VERSION ""

NS_ :

BS_:

BU_: ECU Display VCU SteeringWheel WirelessGateway DATA_COLLECTION_INTEGRAL PDM FanController BMS_Master Competition_Meter FS_Datalogger Chroma LegacyCharger Tools BrakePedalAngleSensor

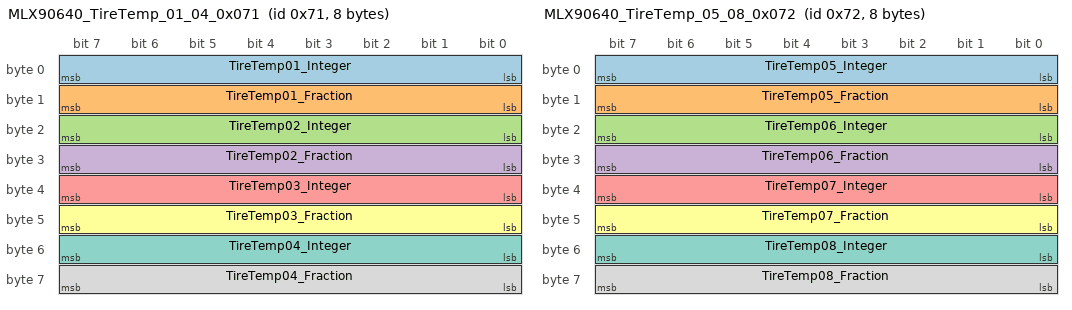
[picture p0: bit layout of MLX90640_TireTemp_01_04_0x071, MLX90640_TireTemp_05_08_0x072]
BO_ 113 MLX90640_TireTemp_01_04_0x071: 8 DATA_COLLECTION_INTEGRAL
 SG_ TireTemp01_Integer : 0|8@1+ (1,0) [0|255] "degC"  Display,WirelessGateway
 SG_ TireTemp01_Fraction : 8|8@1+ (0.01,0) [0|0.99] "degC"  Display,WirelessGateway
 SG_ TireTemp02_Integer : 16|8@1+ (1,0) [0|255] "degC"  Display,WirelessGateway
 SG_ TireTemp02_Fraction : 24|8@1+ (0.01,0) [0|0.99] "degC"  Display,WirelessGateway
 SG_ TireTemp03_Integer : 32|8@1+ (1,0) [0|255] "degC"  Display,WirelessGateway
 SG_ TireTemp03_Fraction : 40|8@1+ (0.01,0) [0|0.99] "degC"  Display,WirelessGateway
 SG_ TireTemp04_Integer : 48|8@1+ (1,0) [0|255] "degC"  Display,WirelessGateway
 SG_ TireTemp04_Fraction : 56|8@1+ (0.01,0) [0|0.99] "degC"  Display,WirelessGateway

BO_ 114 MLX90640_TireTemp_05_08_0x072: 8 DATA_COLLECTION_INTEGRAL
 SG_ TireTemp05_Integer : 0|8@1+ (1,0) [0|255] "degC"  Display,WirelessGateway
 SG_ TireTemp05_Fraction : 8|8@1+ (0.01,0) [0|0.99] "degC"  Display,WirelessGateway
 SG_ TireTemp06_Integer : 16|8@1+ (1,0) [0|255] "degC"  Display,WirelessGateway
 SG_ TireTemp06_Fraction : 24|8@1+ (0.01,0) [0|0.99] "degC"  Display,WirelessGateway
 SG_ TireTemp07_Integer : 32|8@1+ (1,0) [0|255] "degC"  Display,WirelessGateway
 SG_ TireTemp07_Fraction : 40|8@1+ (0.01,0) [0|0.99] "degC"  Display,WirelessGateway
 SG_ TireTemp08_Integer : 48|8@1+ (1,0) [0|255] "degC"  Display,WirelessGateway
 SG_ TireTemp08_Fraction : 56|8@1+ (0.01,0) [0|0.99] "degC"  Display,WirelessGateway

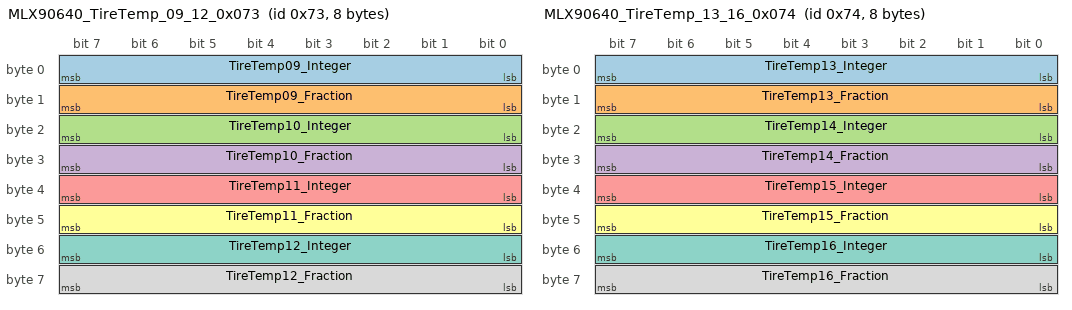
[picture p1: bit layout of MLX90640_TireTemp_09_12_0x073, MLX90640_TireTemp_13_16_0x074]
BO_ 115 MLX90640_TireTemp_09_12_0x073: 8 DATA_COLLECTION_INTEGRAL
 SG_ TireTemp09_Integer : 0|8@1+ (1,0) [0|255] "degC"  Display,WirelessGateway
 SG_ TireTemp09_Fraction : 8|8@1+ (0.01,0) [0|0.99] "degC"  Display,WirelessGateway
 SG_ TireTemp10_Integer : 16|8@1+ (1,0) [0|255] "degC"  Display,WirelessGateway
 SG_ TireTemp10_Fraction : 24|8@1+ (0.01,0) [0|0.99] "degC"  Display,WirelessGateway
 SG_ TireTemp11_Integer : 32|8@1+ (1,0) [0|255] "degC"  Display,WirelessGateway
 SG_ TireTemp11_Fraction : 40|8@1+ (0.01,0) [0|0.99] "degC"  Display,WirelessGateway
 SG_ TireTemp12_Integer : 48|8@1+ (1,0) [0|255] "degC"  Display,WirelessGateway
 SG_ TireTemp12_Fraction : 56|8@1+ (0.01,0) [0|0.99] "degC"  Display,WirelessGateway

BO_ 116 MLX90640_TireTemp_13_16_0x074: 8 DATA_COLLECTION_INTEGRAL
 SG_ TireTemp13_Integer : 0|8@1+ (1,0) [0|255] "degC"  Display,WirelessGateway
 SG_ TireTemp13_Fraction : 8|8@1+ (0.01,0) [0|0.99] "degC"  Display,WirelessGateway
 SG_ TireTemp14_Integer : 16|8@1+ (1,0) [0|255] "degC"  Display,WirelessGateway
 SG_ TireTemp14_Fraction : 24|8@1+ (0.01,0) [0|0.99] "degC"  Display,WirelessGateway
 SG_ TireTemp15_Integer : 32|8@1+ (1,0) [0|255] "degC"  Display,WirelessGateway
 SG_ TireTemp15_Fraction : 40|8@1+ (0.01,0) [0|0.99] "degC"  Display,WirelessGateway
 SG_ TireTemp16_Integer : 48|8@1+ (1,0) [0|255] "degC"  Display,WirelessGateway
 SG_ TireTemp16_Fraction : 56|8@1+ (0.01,0) [0|0.99] "degC"  Display,WirelessGateway

CM_ BO_ 113 "MLX90640 right-front tire-temperature cells 1..4, standard CAN ID 0x071, DLC=8. R0..R3 map directly to cells 1..4 in payload order, from RF rightmost/outside to RF leftmost/inside. Bytes 0/2/4/6 are unsigned integer degC; bytes 1/3/5/7 are unsigned hundredths 0..99. Full temperature = Integer + Fraction.";
CM_ BO_ 114 "MLX90640 left-front tire-temperature cells 5..8, standard CAN ID 0x072, DLC=8. R0..R3 map directly to cells 5..8 in payload order, from LF rightmost/inside to LF leftmost/outside. Bytes 0/2/4/6 are unsigned integer degC; bytes 1/3/5/7 are unsigned hundredths 0..99. Full temperature = Integer + Fraction.";
CM_ BO_ 115 "MLX90640 left-rear tire-temperature cells 9..12, standard CAN ID 0x073, DLC=8. R0..R3 map directly to cells 9..12 in payload order, from LR leftmost/outside to LR rightmost/inside. Bytes 0/2/4/6 are unsigned integer degC; bytes 1/3/5/7 are unsigned hundredths 0..99. Full temperature = Integer + Fraction.";
CM_ BO_ 116 "MLX90640 right-rear tire-temperature cells 13..16, standard CAN ID 0x074, DLC=8. R0..R3 map directly to cells 13..16 in payload order, from RR leftmost/inside to RR rightmost/outside. Bytes 0/2/4/6 are unsigned integer degC; bytes 1/3/5/7 are unsigned hundredths 0..99. Full temperature = Integer + Fraction.";
